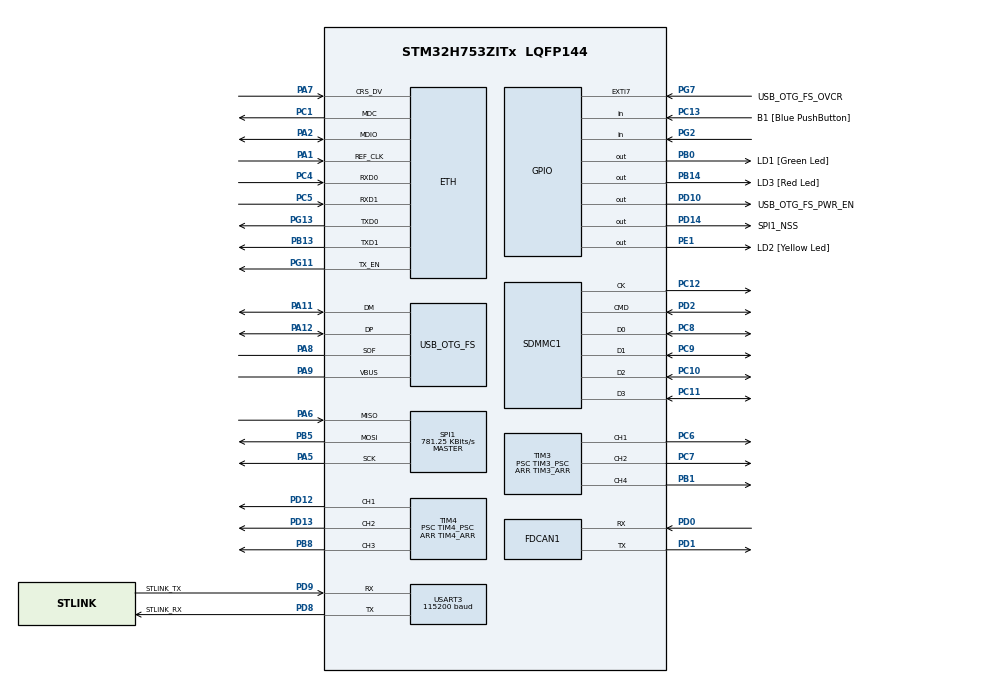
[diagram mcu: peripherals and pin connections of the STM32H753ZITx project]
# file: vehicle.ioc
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CORTEX_M7.AccessPermission-Cortex_Memory_Protection_Unit_Region0_Settings=MPU_REGION_FULL_ACCESS
CORTEX_M7.AccessPermission-Cortex_Memory_Protection_Unit_Region1_Settings=MPU_REGION_FULL_ACCESS
CORTEX_M7.BaseAddress-Cortex_Memory_Protection_Unit_Region0_Settings=0x30000000
CORTEX_M7.BaseAddress-Cortex_Memory_Protection_Unit_Region1_Settings=0x24000000
CORTEX_M7.CPU_DCache=Disabled
CORTEX_M7.CPU_ICache=Disabled
CORTEX_M7.DisableExec-Cortex_Memory_Protection_Unit_Region0_Settings=MPU_INSTRUCTION_ACCESS_DISABLE
CORTEX_M7.DisableExec-Cortex_Memory_Protection_Unit_Region1_Settings=MPU_INSTRUCTION_ACCESS_DISABLE
CORTEX_M7.Enable-Cortex_Memory_Protection_Unit_Region0_Settings=MPU_REGION_ENABLE
CORTEX_M7.Enable-Cortex_Memory_Protection_Unit_Region1_Settings=MPU_REGION_ENABLE
CORTEX_M7.IsShareable-Cortex_Memory_Protection_Unit_Region0_Settings=MPU_ACCESS_SHAREABLE
CORTEX_M7.IsShareable-Cortex_Memory_Protection_Unit_Region1_Settings=MPU_ACCESS_SHAREABLE
CORTEX_M7.MPU_Control=MPU_HFNMI_PRIVDEF
CORTEX_M7.Size-Cortex_Memory_Protection_Unit_Region0_Settings=MPU_REGION_SIZE_64KB
CORTEX_M7.Size-Cortex_Memory_Protection_Unit_Region1_Settings=MPU_REGION_SIZE_512KB
CORTEX_M7.TypeExtField-Cortex_Memory_Protection_Unit_Region1_Settings=MPU_TEX_LEVEL1
Dma.Request0=SPI1_RX
Dma.Request1=SPI1_TX
Dma.SPI1_RX.0.Direction=DMA_PERIPH_TO_MEMORY
Dma.SPI1_RX.0.EventEnable=DISABLE
Dma.SPI1_RX.0.FIFOMode=DMA_FIFOMODE_DISABLE
Dma.SPI1_RX.0.Instance=DMA1_Stream0
Dma.SPI1_RX.0.MemDataAlignment=DMA_MDATAALIGN_BYTE
Dma.SPI1_RX.0.MemInc=DMA_MINC_ENABLE
Dma.SPI1_RX.0.Mode=DMA_NORMAL
Dma.SPI1_RX.0.PeriphDataAlignment=DMA_PDATAALIGN_BYTE
Dma.SPI1_RX.0.PeriphInc=DMA_PINC_DISABLE
Dma.SPI1_RX.0.Polarity=HAL_DMAMUX_REQ_GEN_RISING
Dma.SPI1_RX.0.Priority=DMA_PRIORITY_LOW
Dma.SPI1_RX.0.RequestNumber=1
Dma.SPI1_RX.0.SignalID=NONE
Dma.SPI1_RX.0.SyncEnable=DISABLE
Dma.SPI1_RX.0.SyncPolarity=HAL_DMAMUX_SYNC_NO_EVENT
Dma.SPI1_RX.0.SyncRequestNumber=1
Dma.SPI1_RX.0.SyncSignalID=NONE
Dma.SPI1_TX.1.Direction=DMA_MEMORY_TO_PERIPH
Dma.SPI1_TX.1.EventEnable=DISABLE
Dma.SPI1_TX.1.FIFOMode=DMA_FIFOMODE_DISABLE
Dma.SPI1_TX.1.Instance=DMA1_Stream1
Dma.SPI1_TX.1.MemDataAlignment=DMA_MDATAALIGN_BYTE
Dma.SPI1_TX.1.MemInc=DMA_MINC_ENABLE
Dma.SPI1_TX.1.Mode=DMA_NORMAL
Dma.SPI1_TX.1.PeriphDataAlignment=DMA_PDATAALIGN_BYTE
Dma.SPI1_TX.1.PeriphInc=DMA_PINC_DISABLE
Dma.SPI1_TX.1.Polarity=HAL_DMAMUX_REQ_GEN_RISING
Dma.SPI1_TX.1.Priority=DMA_PRIORITY_LOW
Dma.SPI1_TX.1.RequestNumber=1
Dma.SPI1_TX.1.SignalID=NONE
Dma.SPI1_TX.1.SyncEnable=DISABLE
Dma.SPI1_TX.1.SyncPolarity=HAL_DMAMUX_SYNC_NO_EVENT
Dma.SPI1_TX.1.SyncRequestNumber=1
Dma.SPI1_TX.1.SyncSignalID=NONE
ETH.ETH_RX_DESC_CNT=4
ETH.ETH_TX_DESC_CNT=4
ETH.MACAddr=00\:80\:E1\:00\:00\:00
ETH.MediaInterface=HAL_ETH_RMII_MODE
ETH.RxBuffAddress=0x30040200
ETH.RxBuffLen=1524
ETH.RxDescAddress=0x30040000
ETH.TxDescAddress=0x30040060
FATFS.BSP.number=1
FATFS._MAX_SS=4096
FATFS._USE_LFN=2
FATFS0.BSP.STBoard=false
FATFS0.BSP.api=Unknown
FATFS0.BSP.instance=PG2
FATFS0.BSP.ip=GPIO
FATFS0.BSP.mode=Input
FATFS0.BSP.name=Detect_SDIO
FATFS0.BSP.solution=PG2
FDCAN1.CalculateBaudRateNominal=500000
FDCAN1.CalculateTimeBitNominal=2000
FDCAN1.CalculateTimeQuantumNominal=100.0
FDCAN1.DataPrescaler=2
FDCAN1.DataTimeSeg1=14
FDCAN1.DataTimeSeg2=2
FDCAN1.NominalPrescaler=5
FDCAN1.NominalTimeSeg1=15
FDCAN1.NominalTimeSeg2=4
FDCAN1.ProtocolException=ENABLE
FDCAN1.RxBuffersNbr=FDCAN_RX_BUF_NBR
FDCAN1.RxFifo0ElmtsNbr=FDCAN_RX0_NBR
FDCAN1.RxFifo1ElmtsNbr=FDCAN_RX1_NBR
FDCAN1.StdFiltersNbr=FDCAN_STD_FILTER_NBR
FDCAN1.TransmitPause=ENABLE
FDCAN1.TxBuffersNbr=FDCAN_TX_BUF_NBR
FDCAN1.TxEventsNbr=FDCAN_TX_EVT_NBR
FDCAN1.TxFifoQueueElmtsNbr=FDCAN_TX_FIFO_NBR
FREERTOS.Tasks01=defaultTask,24,128,StartDefaultTask,As weak,NULL,Dynamic,NULL,NULL;SDCardTask,16,512,StartSDCardTask,As weak,NULL,Dynamic,NULL,NULL;FdCanTask,40,256,StartFdCanTask,As weak,NULL,Dynamic,NULL,NULL;VehicleTask,25,128,StartVehicleTask,As weak,NULL,Dynamic,NULL,NULL;Spi1Task,41,512,StartSpi1Task,As weak,NULL,Dynamic,NULL,NULL
FREERTOS.configENABLE_BACKWARD_COMPATIBILITY=0
FREERTOS.configTOTAL_HEAP_SIZE=8192
FREERTOS.configUSE_NEWLIB_REENTRANT=1
Mcu.Family=STM32H7
Mcu.Name=STM32H753ZITx
Mcu.Package=LQFP144
Mdma.MDMA_Channel0.Request0=SDMMC1_END_DATA
Mdma.MDMA_Channel0.Request1=SW
Mdma.MDMA_Channel0.RequestsNb=2
Mdma.MDMA_Channel0.SDMMC1_END_DATA.0.BlockCount=0
Mdma.MDMA_Channel0.SDMMC1_END_DATA.0.BlockDataLength=0
Mdma.MDMA_Channel0.SDMMC1_END_DATA.0.BufferTransferLength=32
Mdma.MDMA_Channel0.SDMMC1_END_DATA.0.CircularMode=MDMA_LINEAR_LIST
Mdma.MDMA_Channel0.SDMMC1_END_DATA.0.DataAlignment=MDMA_DATAALIGN_PACKENABLE
Mdma.MDMA_Channel0.SDMMC1_END_DATA.0.DestBlockAddressOffset=0
Mdma.MDMA_Channel0.SDMMC1_END_DATA.0.DestBurst=MDMA_DEST_BURST_SINGLE
Mdma.MDMA_Channel0.SDMMC1_END_DATA.0.DestDataSize=MDMA_DEST_DATASIZE_WORD
Mdma.MDMA_Channel0.SDMMC1_END_DATA.0.DestinationInc=MDMA_DEST_INC_WORD
Mdma.MDMA_Channel0.SDMMC1_END_DATA.0.DstAddress=0
Mdma.MDMA_Channel0.SDMMC1_END_DATA.0.Endianness=MDMA_LITTLE_ENDIANNESS_PRESERVE
Mdma.MDMA_Channel0.SDMMC1_END_DATA.0.Instance=MDMA_Channel0
Mdma.MDMA_Channel0.SDMMC1_END_DATA.0.MaskAddress=0
Mdma.MDMA_Channel0.SDMMC1_END_DATA.0.MaskData=0
Mdma.MDMA_Channel0.SDMMC1_END_DATA.0.Priority=MDMA_PRIORITY_MEDIUM
Mdma.MDMA_Channel0.SDMMC1_END_DATA.0.Rank=First
Mdma.MDMA_Channel0.SDMMC1_END_DATA.0.SourceBlockAddressOffset=0
Mdma.MDMA_Channel0.SDMMC1_END_DATA.0.SourceBurst=MDMA_SOURCE_BURST_SINGLE
Mdma.MDMA_Channel0.SDMMC1_END_DATA.0.SourceDataSize=MDMA_SRC_DATASIZE_WORD
Mdma.MDMA_Channel0.SDMMC1_END_DATA.0.SourceInc=MDMA_SRC_INC_WORD
Mdma.MDMA_Channel0.SDMMC1_END_DATA.0.SrcAddress=0
Mdma.MDMA_Channel0.SDMMC1_END_DATA.0.TransferTriggerMode=MDMA_BUFFER_TRANSFER
Mdma.MDMA_Channel0.SW.1.BlockCount=0
Mdma.MDMA_Channel0.SW.1.BlockDataLength=0
Mdma.MDMA_Channel0.SW.1.BufferTransferLength=32
Mdma.MDMA_Channel0.SW.1.CircularMode=MDMA_LINEAR_LIST
Mdma.MDMA_Channel0.SW.1.DataAlignment=MDMA_DATAALIGN_PACKENABLE
Mdma.MDMA_Channel0.SW.1.DestBlockAddressOffset=0
Mdma.MDMA_Channel0.SW.1.DestBurst=MDMA_DEST_BURST_SINGLE
Mdma.MDMA_Channel0.SW.1.DestDataSize=MDMA_DEST_DATASIZE_WORD
Mdma.MDMA_Channel0.SW.1.DestinationInc=MDMA_DEST_INC_WORD
Mdma.MDMA_Channel0.SW.1.DstAddress=0
Mdma.MDMA_Channel0.SW.1.Endianness=MDMA_LITTLE_ENDIANNESS_PRESERVE
Mdma.MDMA_Channel0.SW.1.Instance=MDMA_Channel0
Mdma.MDMA_Channel0.SW.1.MaskAddress=0
Mdma.MDMA_Channel0.SW.1.MaskData=0
Mdma.MDMA_Channel0.SW.1.Priority=MDMA_PRIORITY_MEDIUM
Mdma.MDMA_Channel0.SW.1.Rank=Last
Mdma.MDMA_Channel0.SW.1.SourceBlockAddressOffset=0
Mdma.MDMA_Channel0.SW.1.SourceBurst=MDMA_SOURCE_BURST_SINGLE
Mdma.MDMA_Channel0.SW.1.SourceDataSize=MDMA_SRC_DATASIZE_WORD
Mdma.MDMA_Channel0.SW.1.SourceInc=MDMA_SRC_INC_WORD
Mdma.MDMA_Channel0.SW.1.SrcAddress=0
Mdma.MDMA_Channel0.SW.1.TransferTriggerMode=MDMA_BUFFER_TRANSFER
Mdma.MDMA_Channel0.SW.1.node=node_mdma_channel0_sw_1
Mdma.MDMA_Channel0.SW.1.pNewNode=node_mdma_channel0_sw_1
Mdma.RequestSet0=MDMA_Channel0
Mdma.RequestSetsNb=1
NVIC.DMA1_Stream0_IRQn=true\:10\:0\:true\:false\:true\:true\:false\:true\:true
NVIC.DMA1_Stream1_IRQn=true\:10\:0\:true\:false\:true\:true\:false\:true\:true
NVIC.FDCAN1_IT0_IRQn=true\:5\:0\:false\:false\:true\:true\:true\:true\:true
NVIC.FDCAN1_IT1_IRQn=true\:5\:0\:false\:false\:true\:true\:true\:true\:true
NVIC.MDMA_IRQn=true\:5\:0\:true\:false\:true\:true\:false\:true\:true
NVIC.PriorityGroup=NVIC_PRIORITYGROUP_4
NVIC.SDMMC1_IRQn=true\:5\:0\:false\:false\:true\:true\:true\:true\:true
NVIC.SPI1_IRQn=true\:10\:0\:true\:false\:true\:true\:true\:true\:true
NVIC.TIM6_DAC_IRQn=true\:15\:0\:false\:false\:true\:false\:false\:true\:true
NVIC.TimeBase=TIM6_DAC_IRQn
NVIC.TimeBaseIP=TIM6
PA0.GPIO_ModeDefaultPP=GPIO_MODE_AF_OD
PA0.GPIO_PuPd=GPIO_PULLUP
PA0.GPIO_Speed=GPIO_SPEED_FREQ_HIGH
PA0.Signal=S_TIM2_CH1_ETR
PA1.Mode=RMII
PA1.Signal=ETH_REF_CLK
PA11.Mode=Device_Only
PA11.Signal=USB_OTG_FS_DM
PA12.Mode=Device_Only
PA12.Signal=USB_OTG_FS_DP
PA2.Mode=RMII
PA2.Signal=ETH_MDIO
PA5.GPIO_PuPd=GPIO_PULLUP
PA5.GPIO_Speed=GPIO_SPEED_FREQ_VERY_HIGH
PA5.Mode=Full_Duplex_Master
PA5.Signal=SPI1_SCK
PA6.GPIO_PuPd=GPIO_PULLUP
PA6.GPIO_Speed=GPIO_SPEED_FREQ_VERY_HIGH
PA6.Mode=Full_Duplex_Master
PA6.Signal=SPI1_MISO
PA7.Mode=RMII
PA7.Signal=ETH_CRS_DV
PA8.Mode=Activate_SOF_FS
PA8.Signal=USB_OTG_FS_SOF
PA9.Mode=Activate_VBUS
PA9.Signal=USB_OTG_FS_VBUS
PB0.GPIO_Label=LD1 [Green Led]
PB0.Signal=GPIO_Output
PB1.Signal=S_TIM3_CH4
PB13.Mode=RMII
PB13.Signal=ETH_TXD1
PB14.GPIO_Label=LD3 [Red Led]
PB14.Signal=GPIO_Output
PB5.GPIO_PuPd=GPIO_PULLUP
PB5.GPIO_Speed=GPIO_SPEED_FREQ_VERY_HIGH
PB5.Mode=Full_Duplex_Master
PB5.Signal=SPI1_MOSI
PB8.Signal=S_TIM4_CH3
PC1.Mode=RMII
PC1.Signal=ETH_MDC
PC10.Mode=SD_4_bits_Wide_bus
PC10.Signal=SDMMC1_D2
PC11.Mode=SD_4_bits_Wide_bus
PC11.Signal=SDMMC1_D3
PC12.Mode=SD_4_bits_Wide_bus
PC12.Signal=SDMMC1_CK
PC13.GPIO_Label=B1 [Blue PushButton]
PC13.GPIO_PuPd=GPIO_PULLUP
PC13.Signal=GPIO_Input
PC14-OSC32_IN\ (OSC32_IN).Mode=LSE-External-Oscillator
PC14-OSC32_IN\ (OSC32_IN).Signal=RCC_OSC32_IN
PC15-OSC32_OUT\ (OSC32_OUT).Mode=LSE-External-Oscillator
PC15-OSC32_OUT\ (OSC32_OUT).Signal=RCC_OSC32_OUT
PC4.Mode=RMII
PC4.Signal=ETH_RXD0
PC5.Mode=RMII
PC5.Signal=ETH_RXD1
PC6.Signal=S_TIM3_CH1
PC7.Signal=S_TIM3_CH2
PC8.Mode=SD_4_bits_Wide_bus
PC8.Signal=SDMMC1_D0
PC9.Mode=SD_4_bits_Wide_bus
PC9.Signal=SDMMC1_D1
PD0.Mode=FDCAN_Activate
PD0.Signal=FDCAN1_RX
PD1.Mode=FDCAN_Activate
PD1.Signal=FDCAN1_TX
PD10.GPIO_Label=USB_OTG_FS_PWR_EN
PD10.Signal=GPIO_Output
PD12.Signal=S_TIM4_CH1
PD13.Signal=S_TIM4_CH2
PD14.GPIO_Label=SPI1_NSS
PD14.GPIO_PuPd=GPIO_PULLUP
PD14.Signal=GPIO_Output
PD2.Mode=SD_4_bits_Wide_bus
PD2.Signal=SDMMC1_CMD
PD8.GPIO_Label=STLINK_RX
PD8.Mode=Asynchronous
PD8.Signal=USART3_TX
PD9.GPIO_Label=STLINK_TX
PD9.Mode=Asynchronous
PD9.Signal=USART3_RX
PE1.GPIO_Label=LD2 [Yellow Led]
PE1.Signal=GPIO_Output
PG11.Mode=RMII
PG11.Signal=ETH_TX_EN
PG13.Mode=RMII
PG13.Signal=ETH_TXD0
PG2.GPIO_PuPd=GPIO_PULLUP
PG2.Signal=GPIO_Input
PG7.GPIO_Label=USB_OTG_FS_OVCR
PG7.Signal=GPXTI7
PH0-OSC_IN\ (PH0).Mode=HSE-External-Clock-Source
PH0-OSC_IN\ (PH0).Signal=RCC_OSC_IN
PH1-OSC_OUT\ (PH1).Signal=RCC_OSC_OUT
ProjectManager.HeapSize=0x200
ProjectManager.StackSize=0x400
ProjectManager.TargetToolchain=STM32CubeIDE
RCC.ADCFreq_Value=100000000
RCC.APB1Freq_Value=32000000
RCC.APB2Freq_Value=64000000
RCC.APB3Freq_Value=64000000
RCC.APB4Freq_Value=64000000
RCC.CortexFreq_Value=64000000
RCC.D2PPRE1=RCC_APB1_DIV2
RCC.DIVM1=1
RCC.DIVM2=1
RCC.DIVN1=100
RCC.DIVN2=100
RCC.DIVP2=8
RCC.DIVQ1=16
RCC.DIVR2=16
RCC.HCLKFreq_Value=64000000
RCC.HSE_VALUE=8000000
RCC.PLL2FRACN=0
RCC.SPI123CLockSelection=RCC_SPI123CLKSOURCE_PLL2
RCC.SYSCLKFreq_VALUE=64000000
RCC.USBFreq_Value=50000000
SDMMC1.ClockDiv=SDMMC_CLK_DIV
SDMMC1.HardwareFlowControl=SDMMC_HARDWARE_FLOW_CONTROL_DISABLE
SH.S_TIM2_CH1_ETR.0=TIM2_CH1
SH.S_TIM3_CH1.0=TIM3_CH1,PWM Generation1 CH1
SH.S_TIM3_CH2.0=TIM3_CH2,PWM Generation2 CH2
SH.S_TIM3_CH4.0=TIM3_CH4,PWM Generation4 CH4
SH.S_TIM4_CH1.0=TIM4_CH1,PWM Generation1 CH1
SH.S_TIM4_CH2.0=TIM4_CH2,PWM Generation2 CH2
SH.S_TIM4_CH3.0=TIM4_CH3,PWM Generation3 CH3
SPI1.BaudRatePrescaler=SPI_BAUDRATEPRESCALER_128
SPI1.CalculateBaudRate=781.25 KBits/s
SPI1.DataSize=SPI_DATASIZE_8BIT
SPI1.Direction=SPI_DIRECTION_2LINES
SPI1.Mode=SPI_MODE_MASTER
SPI1.NSSPMode=SPI_NSS_PULSE_ENABLE
SPI1.VirtualType=VM_MASTER
STMicroelectronics.X-CUBE-ALGOBUILD.1.4.0.LibraryCcDSPOoLibraryJjDSPOoLibrary=true
TIM3.Channel-PWM\ Generation1\ CH1=TIM_CHANNEL_1
TIM3.Channel-PWM\ Generation2\ CH2=TIM_CHANNEL_2
TIM3.Channel-PWM\ Generation4\ CH4=TIM_CHANNEL_4
TIM3.OCPolarity_1=TIM_OCPOLARITY_LOW
TIM3.OCPolarity_2=TIM_OCPOLARITY_LOW
TIM3.OCPolarity_4=TIM_OCPOLARITY_LOW
TIM3.Period=TIM3_ARR
TIM3.Prescaler=TIM3_PSC
TIM4.Channel-PWM\ Generation1\ CH1=TIM_CHANNEL_1
TIM4.Channel-PWM\ Generation2\ CH2=TIM_CHANNEL_2
TIM4.Channel-PWM\ Generation3\ CH3=TIM_CHANNEL_3
TIM4.OCPolarity_1=TIM_OCPOLARITY_LOW
TIM4.OCPolarity_2=TIM_OCPOLARITY_LOW
TIM4.OCPolarity_3=TIM_OCPOLARITY_LOW
TIM4.Period=TIM4_ARR
TIM4.Prescaler=TIM4_PSC
USART3.AutoBaudRateEnableParam=UART_ADVFEATURE_AUTOBAUDRATE_DISABLE
USART3.BaudRate=115200
USART3.ClockPrescaler=PRESCALER_DIV1
USART3.DMADisableonRxErrorParam=ADVFEATURE_DMA_ENABLEONRXERROR
USART3.DataInvertParam=ADVFEATURE_DATAINV_DISABLE
USART3.FIFOMode=FIFOMODE_DISABLE
USART3.MSBFirstParam=ADVFEATURE_MSBFIRST_DISABLE
USART3.Mode=MODE_TX_RX
USART3.OneBitSampling=UART_ONE_BIT_SAMPLE_DISABLE
USART3.OverSampling=UART_OVERSAMPLING_16
USART3.OverrunDisableParam=ADVFEATURE_OVERRUN_ENABLE
USART3.Parity=PARITY_NONE
USART3.RXFIFOThreshold=RXFIFO_THRESHOLD_1EIGHTHFULL
USART3.RxPinLevelInvertParam=ADVFEATURE_RXINV_DISABLE
USART3.StopBits=STOPBITS_1
USART3.SwapParam=ADVFEATURE_SWAP_DISABLE
USART3.TXFIFOThreshold=TXFIFO_THRESHOLD_1EIGHTHFULL
USART3.TxPinLevelInvertParam=ADVFEATURE_TXINV_DISABLE
USART3.VirtualMode-Asynchronous=VM_ASYNC
USART3.WordLength=WORDLENGTH_8B
USB_OTG_FS.Sof_enable=ENABLE
USB_OTG_FS.VirtualMode=Device_Only
USB_OTG_FS.battery_charging_enable=ENABLE
USB_OTG_FS.low_power_enable=DISABLE
USB_OTG_FS.lpm_enable=DISABLE
USB_OTG_FS.use_dedicated_ep1=DISABLE
USB_OTG_FS.vbus_sensing_enable=ENABLE
VP_FATFS_VS_SDIO.Mode=SDIO
VP_FREERTOS_VS_CMSIS_V2.Mode=CMSIS_V2
VP_MEMORYMAP_VS_MEMORYMAP.Mode=CurAppReg
VP_STMicroelectronics.X-CUBE-ALGOBUILD_VS_DSPOoLibraryJjLibrary_1.4.0_1.4.0.Mode=DSPOoLibraryJjLibrary
VP_SYS_VS_tim6.Mode=TIM6
board=NUCLEO-H753ZI

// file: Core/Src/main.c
/* USER CODE BEGIN Header */
/**
  ******************************************************************************
  * @file           : main.c
  * @brief          : Main program body
  ******************************************************************************
  * @attention
  *
  * Copyright (c) 2025 STMicroelectronics.
  * All rights reserved.
  *
  * This software is licensed under terms that can be found in the LICENSE file
  * in the root directory of this software component.
  * If no LICENSE file comes with this software, it is provided AS-IS.
  *
  ******************************************************************************
  */
/* USER CODE END Header */
#include "main.h"
#include "cmsis_os.h"
#include "dma.h"
#include "eth.h"
#include "fatfs.h"
#include "fdcan.h"
#include "mdma.h"
#include "memorymap.h"
#include "sdmmc.h"
#include "spi.h"
#include "tim.h"
#include "usart.h"
#include "usb_otg.h"
#include "gpio.h"

/* USER CODE BEGIN Includes */
#include "main/main.h"
#include "main/main.h"
#include "HY_MOD/dht/callback.h"
/* USER CODE END Includes */

void SystemClock_Config(void);
static void MPU_Config(void);
void MX_FREERTOS_Init(void);

int main(void)
{

  /* MPU Configuration--------------------------------------------------------*/
  MPU_Config();

  /* MCU Configuration--------------------------------------------------------*/

  /* Reset of all peripherals, Initializes the Flash interface and the Systick. */
  HAL_Init();

  /* Configure the system clock */
  SystemClock_Config();

  /* Initialize all configured peripherals */
  MX_GPIO_Init();
  MX_MDMA_Init();
  MX_DMA_Init();
  MX_ETH_Init();
  MX_USART3_UART_Init();
  MX_USB_OTG_FS_PCD_Init();
  MX_FDCAN1_Init();
  MX_SDMMC1_SD_Init();
  MX_FATFS_Init();
  MX_SPI1_Init();
  MX_TIM3_Init();
  MX_TIM4_Init();
  /* USER CODE BEGIN 2 */
  INIT_OWN();
  /* USER CODE END 2 */

  /* Init scheduler */
  osKernelInitialize();

  /* Call init function for freertos objects (in cmsis_os2.c) */
  MX_FREERTOS_Init();

  /* Start scheduler */
  osKernelStart();

  /* We should never get here as control is now taken by the scheduler */

  /* Infinite loop */
  while (1)
  {

  }
}

void SystemClock_Config(void)
{
  RCC_OscInitTypeDef RCC_OscInitStruct = {0};
  RCC_ClkInitTypeDef RCC_ClkInitStruct = {0};

  /** Supply configuration update enable
  */
  HAL_PWREx_ConfigSupply(PWR_LDO_SUPPLY);

  /** Configure the main internal regulator output voltage
  */
  __HAL_PWR_VOLTAGESCALING_CONFIG(PWR_REGULATOR_VOLTAGE_SCALE3);

  while(!__HAL_PWR_GET_FLAG(PWR_FLAG_VOSRDY)) {}

  /** Initializes the RCC Oscillators according to the specified parameters
  * in the RCC_OscInitTypeDef structure.
  */
  RCC_OscInitStruct.OscillatorType = RCC_OSCILLATORTYPE_HSI|RCC_OSCILLATORTYPE_HSE;
  RCC_OscInitStruct.HSEState = RCC_HSE_BYPASS;
  RCC_OscInitStruct.HSIState = RCC_HSI_DIV1;
  RCC_OscInitStruct.HSICalibrationValue = RCC_HSICALIBRATION_DEFAULT;
  RCC_OscInitStruct.PLL.PLLState = RCC_PLL_ON;
  RCC_OscInitStruct.PLL.PLLSource = RCC_PLLSOURCE_HSE;
  RCC_OscInitStruct.PLL.PLLM = 1;
  RCC_OscInitStruct.PLL.PLLN = 100;
  RCC_OscInitStruct.PLL.PLLP = 2;
  RCC_OscInitStruct.PLL.PLLQ = 16;
  RCC_OscInitStruct.PLL.PLLR = 2;
  RCC_OscInitStruct.PLL.PLLRGE = RCC_PLL1VCIRANGE_3;
  RCC_OscInitStruct.PLL.PLLVCOSEL = RCC_PLL1VCOWIDE;
  RCC_OscInitStruct.PLL.PLLFRACN = 0;
  if (HAL_RCC_OscConfig(&RCC_OscInitStruct) != HAL_OK)
  {
    Error_Handler();
  }

  /** Initializes the CPU, AHB and APB buses clocks
  */
  RCC_ClkInitStruct.ClockType = RCC_CLOCKTYPE_HCLK|RCC_CLOCKTYPE_SYSCLK
                              |RCC_CLOCKTYPE_PCLK1|RCC_CLOCKTYPE_PCLK2
                              |RCC_CLOCKTYPE_D3PCLK1|RCC_CLOCKTYPE_D1PCLK1;
  RCC_ClkInitStruct.SYSCLKSource = RCC_SYSCLKSOURCE_HSI;
  RCC_ClkInitStruct.SYSCLKDivider = RCC_SYSCLK_DIV1;
  RCC_ClkInitStruct.AHBCLKDivider = RCC_HCLK_DIV1;
  RCC_ClkInitStruct.APB3CLKDivider = RCC_APB3_DIV1;
  RCC_ClkInitStruct.APB1CLKDivider = RCC_APB1_DIV2;
  RCC_ClkInitStruct.APB2CLKDivider = RCC_APB2_DIV1;
  RCC_ClkInitStruct.APB4CLKDivider = RCC_APB4_DIV1;

  if (HAL_RCC_ClockConfig(&RCC_ClkInitStruct, FLASH_LATENCY_1) != HAL_OK)
  {
    Error_Handler();
  }
}

 /* MPU Configuration */

void MPU_Config(void)
{
  MPU_Region_InitTypeDef MPU_InitStruct = {0};

  /* Disables the MPU */
  HAL_MPU_Disable();

  /** Initializes and configures the Region and the memory to be protected
  */
  MPU_InitStruct.Enable = MPU_REGION_ENABLE;
  MPU_InitStruct.Number = MPU_REGION_NUMBER0;
  MPU_InitStruct.BaseAddress = 0x30000000;
  MPU_InitStruct.Size = MPU_REGION_SIZE_64KB;
  MPU_InitStruct.SubRegionDisable = 0x0;
  MPU_InitStruct.TypeExtField = MPU_TEX_LEVEL0;
  MPU_InitStruct.AccessPermission = MPU_REGION_FULL_ACCESS;
  MPU_InitStruct.DisableExec = MPU_INSTRUCTION_ACCESS_DISABLE;
  MPU_InitStruct.IsShareable = MPU_ACCESS_SHAREABLE;
  MPU_InitStruct.IsCacheable = MPU_ACCESS_NOT_CACHEABLE;
  MPU_InitStruct.IsBufferable = MPU_ACCESS_NOT_BUFFERABLE;

  HAL_MPU_ConfigRegion(&MPU_InitStruct);

  /** Initializes and configures the Region and the memory to be protected
  */
  MPU_InitStruct.Number = MPU_REGION_NUMBER1;
  MPU_InitStruct.BaseAddress = 0x24000000;
  MPU_InitStruct.Size = MPU_REGION_SIZE_512KB;
  MPU_InitStruct.TypeExtField = MPU_TEX_LEVEL1;

  HAL_MPU_ConfigRegion(&MPU_InitStruct);
  /* Enables the MPU */
  HAL_MPU_Enable(MPU_HFNMI_PRIVDEF);

}

void HAL_TIM_PeriodElapsedCallback(TIM_HandleTypeDef *htim)
{
  if (htim->Instance == TIM6) {
    HAL_IncTick();
  }
  /* USER CODE BEGIN Callback 1 */
  // dht_tim_PE_cb(&dht_h, htim);
  /* USER CODE END Callback 1 */
}

void Error_Handler(void)
{
  __disable_irq();
  while (1)
  {
  }
}

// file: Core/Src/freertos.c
/* USER CODE BEGIN Header */
/**
  ******************************************************************************
  * File Name          : freertos.c
  * Description        : Code for freertos applications
  ******************************************************************************
  * @attention
  *
  * Copyright (c) 2025 STMicroelectronics.
  * All rights reserved.
  *
  * This software is licensed under terms that can be found in the LICENSE file
  * in the root directory of this software component.
  * If no LICENSE file comes with this software, it is provided AS-IS.
  *
  ******************************************************************************
  */
/* USER CODE END Header */

#include "FreeRTOS.h"
#include "task.h"
#include "main.h"
#include "cmsis_os.h"

/* Definitions for defaultTask */
osThreadId_t defaultTaskHandle;
const osThreadAttr_t defaultTask_attributes = {
  .name = "defaultTask",
  .stack_size = 128 * 4,
  .priority = (osPriority_t) osPriorityNormal,
};
/* Definitions for SDCardTask */
osThreadId_t SDCardTaskHandle;
const osThreadAttr_t SDCardTask_attributes = {
  .name = "SDCardTask",
  .stack_size = 512 * 4,
  .priority = (osPriority_t) osPriorityBelowNormal,
};
/* Definitions for FdCanTask */
osThreadId_t FdCanTaskHandle;
const osThreadAttr_t FdCanTask_attributes = {
  .name = "FdCanTask",
  .stack_size = 256 * 4,
  .priority = (osPriority_t) osPriorityHigh,
};
/* Definitions for VehicleTask */
osThreadId_t VehicleTaskHandle;
const osThreadAttr_t VehicleTask_attributes = {
  .name = "VehicleTask",
  .stack_size = 128 * 4,
  .priority = (osPriority_t) osPriorityNormal1,
};
/* Definitions for Spi1Task */
osThreadId_t Spi1TaskHandle;
const osThreadAttr_t Spi1Task_attributes = {
  .name = "Spi1Task",
  .stack_size = 512 * 4,
  .priority = (osPriority_t) osPriorityHigh1,
};

void StartDefaultTask(void *argument);
void StartSDCardTask(void *argument);
void StartFdCanTask(void *argument);
void StartVehicleTask(void *argument);
void StartSpi1Task(void *argument);

void MX_FREERTOS_Init(void); /* (MISRA C 2004 rule 8.1) */

void MX_FREERTOS_Init(void) {

  /* Create the thread(s) */
  /* creation of defaultTask */
  defaultTaskHandle = osThreadNew(StartDefaultTask, NULL, &defaultTask_attributes);

  /* creation of SDCardTask */
  SDCardTaskHandle = osThreadNew(StartSDCardTask, NULL, &SDCardTask_attributes);

  /* creation of FdCanTask */
  FdCanTaskHandle = osThreadNew(StartFdCanTask, NULL, &FdCanTask_attributes);

  /* creation of VehicleTask */
  VehicleTaskHandle = osThreadNew(StartVehicleTask, NULL, &VehicleTask_attributes);

  /* creation of Spi1Task */
  Spi1TaskHandle = osThreadNew(StartSpi1Task, NULL, &Spi1Task_attributes);

}

__weak void StartDefaultTask(void *argument)
{
  for(;;)
  {
    osDelay(1);
  }
}

__weak void StartSDCardTask(void *argument)
{
  for(;;)
  {
    osDelay(1);
  }
}

__weak void StartFdCanTask(void *argument)
{
  for(;;)
  {
    osDelay(1);
  }
}

__weak void StartVehicleTask(void *argument)
{
  for(;;)
  {
    osDelay(1);
  }
}

__weak void StartSpi1Task(void *argument)
{
  for(;;)
  {
    osDelay(1);
  }
}
